# ESP32S31_RADIO register map
Vendor: Espressif; Series: ESP32-S31; File version: 3.52
Registers are 32-bit, read-write, no defined reset value unless marked. A register's access mark holds for its fields unless they carry their own. Offsets are from the block's base; [hi:lo] are bit positions.

## WIFI_MAC_INTERRUPT — Wi-Fi MAC interrupt mask, masked status and write-to-clear aperture. The two complete hal_mac leaves independently prove the status and clear addresses. The recovered common FIQ and cold initializer prove the event-bit mapping and mask transaction used by the open ISR.
Base 0x20104C40
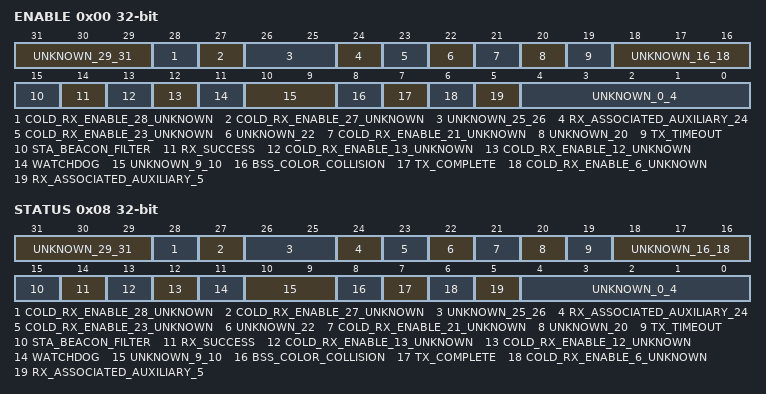
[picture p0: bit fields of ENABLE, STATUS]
0x00 ENABLE — Complete hal_init first publishes 0x19a879e0 here before its remaining tail. Complete hal_enable_mac independently publishes its argument after clearing the shared MAC disable gates. The common FIQ samples it with each interrupt status snapshot.
  [31:29] UNKNOWN_29_31 — Interrupt-enable bits whose event identities remain unknown.
  [28] COLD_RX_ENABLE_28_UNKNOWN — Unknown event enabled by the complete cold receive mask.
  [27] COLD_RX_ENABLE_27_UNKNOWN — Unknown event enabled by the complete cold receive mask.
  [26:25] UNKNOWN_25_26 — Interrupt-enable bits whose event identities remain unknown.
  [24] RX_ASSOCIATED_AUXILIARY_24 — Enable for the status bit observed together with RX_SUCCESS during sustained receive traffic.
  [23] COLD_RX_ENABLE_23_UNKNOWN — Unknown event enabled by the complete cold receive mask.
  [22] UNKNOWN_22 — Interrupt-enable bit whose event identity remains unknown.
  [21] COLD_RX_ENABLE_21_UNKNOWN — Unknown event enabled by the complete cold receive mask.
  [20] UNKNOWN_20 — Interrupt-enable bit whose event identity remains unknown.
  [19] TX_TIMEOUT — Enable for the hardware TX queue timeout/abort event.
  [18:16] UNKNOWN_16_18 — Interrupt-enable bits whose event identities remain unknown.
  [15] STA_BEACON_FILTER — Enable for the station beacon-filter event; the complete disable leaf clears this bit after disabling the filter hardware.
  [14] RX_SUCCESS — Enable for successful receive completion.
  [13] COLD_RX_ENABLE_13_UNKNOWN — Unknown event enabled by the complete cold receive mask.
  [12] COLD_RX_ENABLE_12_UNKNOWN — Unknown event enabled by the complete cold receive mask.
  [11] WATCHDOG — Enable for the MAC watchdog event.
  [10:9] UNKNOWN_9_10 — Interrupt-enable bits whose event identities remain unknown.
  [8] BSS_COLOR_COLLISION — Enable for the HE BSS-color collision event.
  [7] TX_COMPLETE — Enable for the TX-complete event.
  [6] COLD_RX_ENABLE_6_UNKNOWN — Unknown event enabled by the complete cold receive mask.
  [5] RX_ASSOCIATED_AUXILIARY_5 — Enable for the status bit observed together with RX_SUCCESS during sustained receive traffic.
  [4:0] UNKNOWN_0_4 — Interrupt-enable bits whose event identities remain unknown.
0x04 RAW — Unmasked WDEV interrupt snapshot read by print_isr_regs. Complete hal_disable_mac writes zero after masking ENABLE.
  [31:0] EVENTS
0x08 STATUS ro — Masked MAC event snapshot read by the complete hal_mac_interrupt_get_event leaf. Its bit geometry matches the complete ENABLE event bank; only independently recovered event identities are named semantically.
  [31:29] UNKNOWN_29_31 — Masked event bits whose identities remain unknown.
  [28] COLD_RX_ENABLE_28_UNKNOWN — Masked event bit enabled by the complete cold receive mask; its event identity remains unknown.
  [27] COLD_RX_ENABLE_27_UNKNOWN — Masked event bit enabled by the complete cold receive mask; its event identity remains unknown.
  [26:25] UNKNOWN_25_26 — Masked event bits whose identities remain unknown.
  [24] RX_ASSOCIATED_AUXILIARY_24 — Enabled by the cold MAC mask 0x19a879e0 and observed asserted with RX_SUCCESS throughout sustained HE20 receive traffic. Complete wDev_ProcessFiq acknowledges this bit as part of the full STATUS image but does not dispatch independent work for it. Its hardware meaning and independent transition rules remain unknown; software must not treat it as RX ownership or work multiplicity.
  [23] COLD_RX_ENABLE_23_UNKNOWN — Masked event bit enabled by the complete cold receive mask; its event identity remains unknown.
  [22] UNKNOWN_22 — Masked event bit whose identity remains unknown.
  [21] COLD_RX_ENABLE_21_UNKNOWN — Masked event bit enabled by the complete cold receive mask; its event identity remains unknown.
  [20] UNKNOWN_20 — Masked event bit whose identity remains unknown.
  [19] TX_TIMEOUT — Hardware TX queue timeout/abort event.
  [18:16] UNKNOWN_16_18 — Masked event bits whose identities remain unknown.
  [15] STA_BEACON_FILTER — Masked station beacon-filter event. The paired ENABLE field identity is recovered from the complete disable leaf; no task-side dispatch is claimed here.
  [14] RX_SUCCESS — Successfully received frame is ready for the RX completion path.
  [13] COLD_RX_ENABLE_13_UNKNOWN — Masked event bit enabled by the complete cold receive mask; its event identity remains unknown.
  [12] COLD_RX_ENABLE_12_UNKNOWN — Masked event bit enabled by the complete cold receive mask; its event identity remains unknown.
  [11] WATCHDOG — MAC watchdog event cleared by the complete dedicated leaf.
  [10:9] UNKNOWN_9_10 — Masked event bits whose identities remain unknown.
  [8] BSS_COLOR_COLLISION — HE BSS-color collision event.
  [7] TX_COMPLETE — At least one hardware TX queue completed.
  [6] COLD_RX_ENABLE_6_UNKNOWN — Masked event bit enabled by the complete cold receive mask; its event identity remains unknown.
  [5] RX_ASSOCIATED_AUXILIARY_5 — Enabled by the cold MAC mask 0x19a879e0 and observed asserted with RX_SUCCESS throughout sustained HE20 receive traffic. Complete wDev_ProcessFiq acknowledges this bit as part of the full STATUS image but does not dispatch independent work for it. Its hardware meaning and independent transition rules remain unknown; software must not treat it as RX ownership or work multiplicity.
  [4:0] UNKNOWN_0_4 — Masked event bits whose identities remain unknown.
0x0C CLEAR wo write-1-clears — Full event snapshot written by the complete clear leaf to acknowledge pending MAC events.
  [31:0] EVENTS — Ones acknowledge the corresponding event bits.
